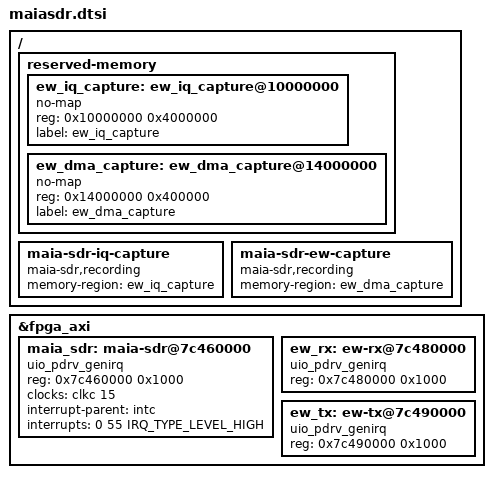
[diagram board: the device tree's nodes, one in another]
/*
 * ZYNQ Pluto SDR (Z7010/AD9363) - Maia SDR (EW Mode)
 *
 * Copyright (C) 2022 Daniel Estevez <daniel@destevez.net>
 *
 * Licensed under the GPL-2.
*/

&fpga_axi {
      /delete-node/ i2c@41600000;
        /delete-node/ mwipcore@43c00000;
        maia_sdr: maia-sdr@7c460000 {
                compatible = "uio_pdrv_genirq";
                reg = <0x7c460000 0x1000>;
                clocks = <&clkc 15>;
                interrupt-parent = <&intc>;
                interrupts = <0 55 IRQ_TYPE_LEVEL_HIGH>;
        };

        ew_rx: ew-rx@7c480000 {
                compatible = "uio_pdrv_genirq";
                reg = <0x7c480000 0x1000>;
                reg-names = "ew-rx-csr";
        };

        ew_tx: ew-tx@7c490000 {
                compatible = "uio_pdrv_genirq";
                reg = <0x7c490000 0x1000>;
                reg-names = "ew-tx-csr";
        };
};

/ {
        reserved-memory {
                #address-cells = <1>;
                #size-cells = <1>;
                ranges;

                ew_iq_capture: ew_iq_capture@10000000 {
                        no-map;
                        reg = <0x10000000 0x4000000>;
                        label = "ew_iq_capture";
                };

                ew_dma_capture: ew_dma_capture@14000000 {
                        no-map;
                        reg = <0x14000000 0x400000>;
                        label = "ew_dma_capture";
                };
        };

        maia-sdr-iq-capture {
                compatible = "maia-sdr,recording";
                memory-region = <&ew_iq_capture>;
        };

        maia-sdr-ew-capture {
                compatible = "maia-sdr,recording";
                memory-region = <&ew_dma_capture>;
        };
};
